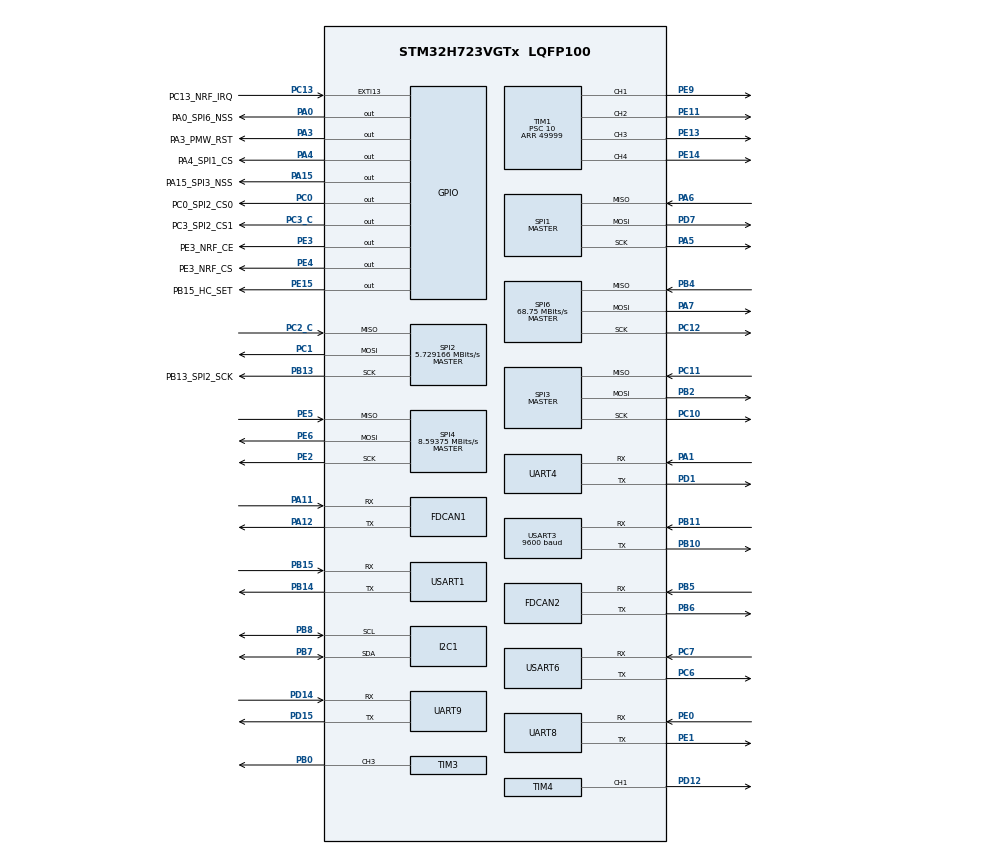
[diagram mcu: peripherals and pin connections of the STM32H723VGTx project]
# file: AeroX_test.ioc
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CORTEX_M7.default_mode_Activation=1
Dma.Request0=TIM4_CH1
Dma.Request1=UART4_RX
Dma.Request2=USART1_RX
Dma.TIM4_CH1.0.Direction=DMA_PERIPH_TO_MEMORY
Dma.TIM4_CH1.0.EventEnable=DISABLE
Dma.TIM4_CH1.0.FIFOMode=DMA_FIFOMODE_DISABLE
Dma.TIM4_CH1.0.Instance=DMA1_Stream0
Dma.TIM4_CH1.0.MemDataAlignment=DMA_MDATAALIGN_WORD
Dma.TIM4_CH1.0.MemInc=DMA_MINC_ENABLE
Dma.TIM4_CH1.0.Mode=DMA_CIRCULAR
Dma.TIM4_CH1.0.PeriphDataAlignment=DMA_PDATAALIGN_WORD
Dma.TIM4_CH1.0.PeriphInc=DMA_PINC_DISABLE
Dma.TIM4_CH1.0.Polarity=HAL_DMAMUX_REQ_GEN_RISING
Dma.TIM4_CH1.0.Priority=DMA_PRIORITY_LOW
Dma.TIM4_CH1.0.RequestNumber=1
Dma.TIM4_CH1.0.SignalID=NONE
Dma.TIM4_CH1.0.SyncEnable=DISABLE
Dma.TIM4_CH1.0.SyncPolarity=HAL_DMAMUX_SYNC_NO_EVENT
Dma.TIM4_CH1.0.SyncRequestNumber=1
Dma.TIM4_CH1.0.SyncSignalID=NONE
Dma.UART4_RX.1.Direction=DMA_PERIPH_TO_MEMORY
Dma.UART4_RX.1.EventEnable=DISABLE
Dma.UART4_RX.1.FIFOMode=DMA_FIFOMODE_DISABLE
Dma.UART4_RX.1.Instance=DMA1_Stream1
Dma.UART4_RX.1.MemDataAlignment=DMA_MDATAALIGN_BYTE
Dma.UART4_RX.1.MemInc=DMA_MINC_ENABLE
Dma.UART4_RX.1.Mode=DMA_CIRCULAR
Dma.UART4_RX.1.PeriphDataAlignment=DMA_PDATAALIGN_BYTE
Dma.UART4_RX.1.PeriphInc=DMA_PINC_DISABLE
Dma.UART4_RX.1.Polarity=HAL_DMAMUX_REQ_GEN_RISING
Dma.UART4_RX.1.Priority=DMA_PRIORITY_VERY_HIGH
Dma.UART4_RX.1.RequestNumber=1
Dma.UART4_RX.1.SignalID=NONE
Dma.UART4_RX.1.SyncEnable=DISABLE
Dma.UART4_RX.1.SyncPolarity=HAL_DMAMUX_SYNC_NO_EVENT
Dma.UART4_RX.1.SyncRequestNumber=1
Dma.UART4_RX.1.SyncSignalID=NONE
Dma.USART1_RX.2.Direction=DMA_PERIPH_TO_MEMORY
Dma.USART1_RX.2.EventEnable=DISABLE
Dma.USART1_RX.2.FIFOMode=DMA_FIFOMODE_DISABLE
Dma.USART1_RX.2.Instance=DMA1_Stream2
Dma.USART1_RX.2.MemDataAlignment=DMA_MDATAALIGN_BYTE
Dma.USART1_RX.2.MemInc=DMA_MINC_ENABLE
Dma.USART1_RX.2.Mode=DMA_NORMAL
Dma.USART1_RX.2.PeriphDataAlignment=DMA_PDATAALIGN_BYTE
Dma.USART1_RX.2.PeriphInc=DMA_PINC_DISABLE
Dma.USART1_RX.2.Polarity=HAL_DMAMUX_REQ_GEN_RISING
Dma.USART1_RX.2.Priority=DMA_PRIORITY_VERY_HIGH
Dma.USART1_RX.2.RequestNumber=1
Dma.USART1_RX.2.SignalID=NONE
Dma.USART1_RX.2.SyncEnable=DISABLE
Dma.USART1_RX.2.SyncPolarity=HAL_DMAMUX_SYNC_NO_EVENT
Dma.USART1_RX.2.SyncRequestNumber=1
Dma.USART1_RX.2.SyncSignalID=NONE
FDCAN1.CalculateBaudRateNominal=1612500
FDCAN1.CalculateTimeBitNominal=620
FDCAN1.CalculateTimeQuantumNominal=124.03100775193798
FDCAN2.CalculateBaudRateNominal=1612500
FDCAN2.CalculateTimeBitNominal=620
FDCAN2.CalculateTimeQuantumNominal=124.03100775193798
FREERTOS.Tasks01=defaultTask,24,512,StartDefaultTask,As weak,NULL,Dynamic,NULL,NULL;AttitudeIMUTask,32,512,StartAttitudeIMUTask,As weak,NULL,Dynamic,NULL,NULL;StabilizeTask,24,512,StartStabilizeTask,As weak,NULL,Dynamic,NULL,NULL;CommuCheckTask,8,256,StartCommuCheckTask,As weak,NULL,Dynamic,NULL,NULL;NrfResponseTask,8,256,StartNrfResponseTask,As weak,NULL,Dynamic,NULL,NULL;MoveTask,30,512,StartMoveTask,As weak,NULL,Dynamic,NULL,NULL
I2C1.Timing=0x60404E72
Mcu.Family=STM32H7
Mcu.Name=STM32H723VGTx
Mcu.Package=LQFP100
NVIC.DMA1_Stream0_IRQn=true\:5\:0\:false\:false\:true\:true\:false\:true\:true
NVIC.DMA1_Stream1_IRQn=true\:5\:0\:false\:false\:true\:true\:false\:true\:true
NVIC.DMA1_Stream2_IRQn=true\:5\:0\:false\:false\:true\:true\:false\:true\:true
NVIC.EXTI15_10_IRQn=true\:5\:0\:false\:false\:true\:true\:true\:true\:true
NVIC.PriorityGroup=NVIC_PRIORITYGROUP_4
NVIC.TIM6_DAC_IRQn=true\:5\:0\:false\:false\:true\:true\:true\:true\:true
NVIC.TIM7_IRQn=true\:15\:0\:false\:false\:true\:false\:false\:true\:true
NVIC.TimeBase=TIM7_IRQn
NVIC.TimeBaseIP=TIM7
NVIC.UART4_IRQn=true\:5\:0\:true\:false\:true\:true\:true\:true\:true
NVIC.UART8_IRQn=true\:5\:0\:false\:false\:true\:true\:true\:true\:true
NVIC.USART1_IRQn=true\:5\:0\:false\:false\:true\:true\:true\:true\:true
PA0.GPIO_Label=PA0_SPI6_NSS
PA0.Signal=GPIO_Output
PA1.Mode=Asynchronous
PA1.Signal=UART4_RX
PA11.Mode=FDCAN_Activate
PA11.Signal=FDCAN1_RX
PA12.Mode=FDCAN_Activate
PA12.Signal=FDCAN1_TX
PA13(JTMS/SWDIO).Mode=Serial_Wire
PA13(JTMS/SWDIO).Signal=DEBUG_JTMS-SWDIO
PA14(JTCK/SWCLK).Mode=Serial_Wire
PA14(JTCK/SWCLK).Signal=DEBUG_JTCK-SWCLK
PA15(JTDI).GPIO_Label=PA15_SPI3_NSS
PA15(JTDI).Signal=GPIO_Output
PA3.GPIO_Label=PA3_PMW_RST
PA3.Signal=GPIO_Output
PA4.GPIO_Label=PA4_SPI1_CS
PA4.Signal=GPIO_Output
PA5.Mode=Full_Duplex_Master
PA5.Signal=SPI1_SCK
PA6.Mode=Full_Duplex_Master
PA6.Signal=SPI1_MISO
PA7.Mode=Full_Duplex_Master
PA7.Signal=SPI6_MOSI
PB0.Signal=S_TIM3_CH3
PB10.Mode=Asynchronous
PB10.Signal=USART3_TX
PB11.Mode=Asynchronous
PB11.Signal=USART3_RX
PB13.GPIO_Label=PB13_SPI2_SCK
PB13.Mode=Full_Duplex_Master
PB13.Signal=SPI2_SCK
PB14.Mode=Asynchronous
PB14.Signal=USART1_TX
PB15.Mode=Asynchronous
PB15.Signal=USART1_RX
PB2.Mode=Full_Duplex_Master
PB2.Signal=SPI3_MOSI
PB4(NJTRST).Mode=Full_Duplex_Master
PB4(NJTRST).Signal=SPI6_MISO
PB5.Mode=FDCAN_Activate
PB5.Signal=FDCAN2_RX
PB6.Mode=FDCAN_Activate
PB6.Signal=FDCAN2_TX
PB7.Mode=I2C
PB7.Signal=I2C1_SDA
PB8.Mode=I2C
PB8.Signal=I2C1_SCL
PC0.GPIO_Label=PC0_SPI2_CS0
PC0.Signal=GPIO_Output
PC1.Mode=Full_Duplex_Master
PC1.Signal=SPI2_MOSI
PC10.Mode=Full_Duplex_Master
PC10.Signal=SPI3_SCK
PC11.Mode=Full_Duplex_Master
PC11.Signal=SPI3_MISO
PC12.Mode=Full_Duplex_Master
PC12.Signal=SPI6_SCK
PC13.GPIO_Label=PC13_NRF_IRQ
PC13.GPIO_ModeDefaultEXTI=GPIO_MODE_IT_FALLING
PC13.Signal=GPXTI13
PC2_C.Mode=Full_Duplex_Master
PC2_C.Signal=SPI2_MISO
PC3_C.GPIO_Label=PC3_SPI2_CS1
PC3_C.Signal=GPIO_Output
PC6.Mode=Asynchronous
PC6.Signal=USART6_TX
PC7.Mode=Asynchronous
PC7.Signal=USART6_RX
PD1.Mode=Asynchronous
PD1.Signal=UART4_TX
PD12.Signal=S_TIM4_CH1
PD14.Mode=Asynchronous
PD14.Signal=UART9_RX
PD15.Mode=Asynchronous
PD15.Signal=UART9_TX
PD7.Mode=Full_Duplex_Master
PD7.Signal=SPI1_MOSI
PE0.Mode=Asynchronous
PE0.Signal=UART8_RX
PE1.Mode=Asynchronous
PE1.Signal=UART8_TX
PE11.Signal=S_TIM1_CH2
PE13.Signal=S_TIM1_CH3
PE14.Signal=S_TIM1_CH4
PE15.GPIO_Label=PB15_HC_SET
PE15.PinState=GPIO_PIN_SET
PE15.Signal=GPIO_Output
PE2.Mode=Full_Duplex_Master
PE2.Signal=SPI4_SCK
PE3.GPIO_Label=PE3_NRF_CE
PE3.Signal=GPIO_Output
PE4.GPIO_Label=PE3_NRF_CS
PE4.Signal=GPIO_Output
PE5.Mode=Full_Duplex_Master
PE5.Signal=SPI4_MISO
PE6.Mode=Full_Duplex_Master
PE6.Signal=SPI4_MOSI
PE9.Signal=S_TIM1_CH1
ProjectManager.HeapSize=0x200
ProjectManager.StackSize=0x400
ProjectManager.TargetToolchain=MDK-ARM V5.32
RCC.ADCFreq_Value=129000000
RCC.APB1Freq_Value=137500000
RCC.APB2Freq_Value=137500000
RCC.APB3Freq_Value=137500000
RCC.APB4Freq_Value=137500000
RCC.CortexFreq_Value=550000000
RCC.D1PPRE=RCC_APB3_DIV2
RCC.D2PPRE1=RCC_APB1_DIV2
RCC.D2PPRE2=RCC_APB2_DIV2
RCC.D3PPRE=RCC_APB4_DIV2
RCC.DIVM1=4
RCC.DIVN1=34
RCC.DIVP1=1
RCC.DIVQ1=3
RCC.FDCANCLockSelection=RCC_FDCANCLKSOURCE_PLL2
RCC.HCLKFreq_Value=275000000
RCC.HPRE=RCC_HCLK_DIV2
RCC.HSE_VALUE=24000000
RCC.PLL2FRACN=0
RCC.PLL3FRACN=0
RCC.PLLFRACN=3072
RCC.SYSCLKFreq_VALUE=550000000
RCC.SYSCLKSource=RCC_SYSCLKSOURCE_PLLCLK
RCC.USBCLockSelection=RCC_USBCLKSOURCE_HSI48
RCC.USBFreq_Value=48000000
SH.S_TIM1_CH1.0=TIM1_CH1,PWM Generation1 CH1
SH.S_TIM1_CH2.0=TIM1_CH2,PWM Generation2 CH2
SH.S_TIM1_CH3.0=TIM1_CH3,PWM Generation3 CH3
SH.S_TIM1_CH4.0=TIM1_CH4,PWM Generation4 CH4
SH.S_TIM3_CH3.0=TIM3_CH3,PWM Generation3 CH3
SH.S_TIM4_CH1.0=TIM4_CH1,PWM Generation1 CH1
SPI1.CalculateBaudRate=91.666664 MBits/s
SPI1.Direction=SPI_DIRECTION_2LINES
SPI1.Mode=SPI_MODE_MASTER
SPI1.VirtualType=VM_MASTER
SPI2.BaudRatePrescaler=SPI_BAUDRATEPRESCALER_32
SPI2.CLKPhase=SPI_PHASE_2EDGE
SPI2.CLKPolarity=SPI_POLARITY_HIGH
SPI2.CalculateBaudRate=5.729166 MBits/s
SPI2.DataSize=SPI_DATASIZE_8BIT
SPI2.Direction=SPI_DIRECTION_2LINES
SPI2.Mode=SPI_MODE_MASTER
SPI2.VirtualType=VM_MASTER
SPI3.CalculateBaudRate=91.666664 MBits/s
SPI3.Direction=SPI_DIRECTION_2LINES
SPI3.Mode=SPI_MODE_MASTER
SPI3.VirtualType=VM_MASTER
SPI4.BaudRatePrescaler=SPI_BAUDRATEPRESCALER_16
SPI4.CalculateBaudRate=8.59375 MBits/s
SPI4.DataSize=SPI_DATASIZE_8BIT
SPI4.Direction=SPI_DIRECTION_2LINES
SPI4.Mode=SPI_MODE_MASTER
SPI4.VirtualType=VM_MASTER
SPI6.CalculateBaudRate=68.75 MBits/s
SPI6.Direction=SPI_DIRECTION_2LINES
SPI6.Mode=SPI_MODE_MASTER
SPI6.VirtualType=VM_MASTER
TIM1.Channel-PWM\ Generation1\ CH1=TIM_CHANNEL_1
TIM1.Channel-PWM\ Generation2\ CH2=TIM_CHANNEL_2
TIM1.Channel-PWM\ Generation3\ CH3=TIM_CHANNEL_3
TIM1.Channel-PWM\ Generation4\ CH4=TIM_CHANNEL_4
TIM1.Period=49999
TIM1.Prescaler=10
TIM3.Channel-PWM\ Generation3\ CH3=TIM_CHANNEL_3
TIM3.Period=343
TIM4.Channel-PWM\ Generation1\ CH1=TIM_CHANNEL_1
TIM4.Period=343
USART1.VirtualMode-Asynchronous=VM_ASYNC
USART3.BaudRate=9600
USART3.VirtualMode-Asynchronous=VM_ASYNC
USART6.VirtualMode=VM_ASYNC
VP_FREERTOS_VS_CMSIS_V2.Mode=CMSIS_V2
VP_MEMORYMAP_VS_MEMORYMAP.Mode=CurAppReg
VP_SYS_VS_tim7.Mode=TIM7
VP_TIM1_VS_ClockSourceINT.Mode=Internal
VP_TIM3_VS_ClockSourceINT.Mode=Internal
VP_TIM6_VS_ClockSourceINT.Mode=Enable_Timer
board=custom

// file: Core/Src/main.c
/* USER CODE BEGIN Header */
/**
  ******************************************************************************
  * @file           : main.c
  * @brief          : Main program body
  ******************************************************************************
  * @attention
  *
  * Copyright (c) 2025 STMicroelectronics.
  * All rights reserved.
  *
  * This software is licensed under terms that can be found in the LICENSE file
  * in the root directory of this software component.
  * If no LICENSE file comes with this software, it is provided AS-IS.
  *
  ******************************************************************************
  */
/* USER CODE END Header */
#include "main.h"
#include "cmsis_os.h"
#include "dma.h"
#include "fdcan.h"
#include "i2c.h"
#include "memorymap.h"
#include "spi.h"
#include "tim.h"
#include "usart.h"
#include "gpio.h"

/* USER CODE BEGIN Includes */
#include "test.h"
#include "appCallback.h"
/* USER CODE END Includes */

void SystemClock_Config(void);
void PeriphCommonClock_Config(void);
static void MPU_Config(void);
void MX_FREERTOS_Init(void);

int main(void)
{

  /* MPU Configuration--------------------------------------------------------*/
  MPU_Config();

  /* MCU Configuration--------------------------------------------------------*/

  /* Reset of all peripherals, Initializes the Flash interface and the Systick. */
  HAL_Init();

  /* Configure the system clock */
  SystemClock_Config();

  /* Configure the peripherals common clocks */
  PeriphCommonClock_Config();

  /* USER CODE BEGIN SysInit */
	if (__HAL_RCC_GET_FLAG(RCC_FLAG_BORRST) != RESET)
  {
	  __HAL_RCC_CLEAR_RESET_FLAGS();
	  HAL_Delay(200);
	  HAL_NVIC_SystemReset();
  }

  /* USER CODE END SysInit */

  /* Initialize all configured peripherals */
  MX_GPIO_Init();
  MX_DMA_Init();
  MX_SPI2_Init();
  MX_TIM1_Init();
  MX_TIM6_Init();
  MX_USART1_UART_Init();
  MX_USART3_UART_Init();
  MX_TIM3_Init();
  MX_SPI1_Init();
  MX_I2C1_Init();
  MX_SPI3_Init();
  MX_SPI4_Init();
  MX_SPI6_Init();
  MX_TIM4_Init();
  MX_UART4_Init();
  MX_UART8_Init();
  MX_UART9_Init();
  MX_USART6_UART_Init();
  MX_FDCAN1_Init();
  MX_FDCAN2_Init();

  /* Init scheduler */
  osKernelInitialize();

  /* Call init function for freertos objects (in cmsis_os2.c) */
  MX_FREERTOS_Init();

  /* Start scheduler */
  osKernelStart();

  /* We should never get here as control is now taken by the scheduler */

  /* Infinite loop */
  while (1)
  {

  }
}

void SystemClock_Config(void)
{
  RCC_OscInitTypeDef RCC_OscInitStruct = {0};
  RCC_ClkInitTypeDef RCC_ClkInitStruct = {0};

  /** Supply configuration update enable
  */
  HAL_PWREx_ConfigSupply(PWR_LDO_SUPPLY);

  /** Configure the main internal regulator output voltage
  */
  __HAL_PWR_VOLTAGESCALING_CONFIG(PWR_REGULATOR_VOLTAGE_SCALE0);

  while(!__HAL_PWR_GET_FLAG(PWR_FLAG_VOSRDY)) {}

  /** Initializes the RCC Oscillators according to the specified parameters
  * in the RCC_OscInitTypeDef structure.
  */
  RCC_OscInitStruct.OscillatorType = RCC_OSCILLATORTYPE_HSI;
  RCC_OscInitStruct.HSIState = RCC_HSI_DIV1;
  RCC_OscInitStruct.HSICalibrationValue = 64;
  RCC_OscInitStruct.PLL.PLLState = RCC_PLL_ON;
  RCC_OscInitStruct.PLL.PLLSource = RCC_PLLSOURCE_HSI;
  RCC_OscInitStruct.PLL.PLLM = 4;
  RCC_OscInitStruct.PLL.PLLN = 34;
  RCC_OscInitStruct.PLL.PLLP = 1;
  RCC_OscInitStruct.PLL.PLLQ = 3;
  RCC_OscInitStruct.PLL.PLLR = 2;
  RCC_OscInitStruct.PLL.PLLRGE = RCC_PLL1VCIRANGE_3;
  RCC_OscInitStruct.PLL.PLLVCOSEL = RCC_PLL1VCOWIDE;
  RCC_OscInitStruct.PLL.PLLFRACN = 3072;
  if (HAL_RCC_OscConfig(&RCC_OscInitStruct) != HAL_OK)
  {
    Error_Handler();
  }

  /** Initializes the CPU, AHB and APB buses clocks
  */
  RCC_ClkInitStruct.ClockType = RCC_CLOCKTYPE_HCLK|RCC_CLOCKTYPE_SYSCLK
                              |RCC_CLOCKTYPE_PCLK1|RCC_CLOCKTYPE_PCLK2
                              |RCC_CLOCKTYPE_D3PCLK1|RCC_CLOCKTYPE_D1PCLK1;
  RCC_ClkInitStruct.SYSCLKSource = RCC_SYSCLKSOURCE_PLLCLK;
  RCC_ClkInitStruct.SYSCLKDivider = RCC_SYSCLK_DIV1;
  RCC_ClkInitStruct.AHBCLKDivider = RCC_HCLK_DIV2;
  RCC_ClkInitStruct.APB3CLKDivider = RCC_APB3_DIV2;
  RCC_ClkInitStruct.APB1CLKDivider = RCC_APB1_DIV2;
  RCC_ClkInitStruct.APB2CLKDivider = RCC_APB2_DIV2;
  RCC_ClkInitStruct.APB4CLKDivider = RCC_APB4_DIV2;

  if (HAL_RCC_ClockConfig(&RCC_ClkInitStruct, FLASH_LATENCY_3) != HAL_OK)
  {
    Error_Handler();
  }
}

void PeriphCommonClock_Config(void)
{
  RCC_PeriphCLKInitTypeDef PeriphClkInitStruct = {0};

  /** Initializes the peripherals clock
  */
  PeriphClkInitStruct.PeriphClockSelection = RCC_PERIPHCLK_FDCAN;
  PeriphClkInitStruct.PLL2.PLL2M = 32;
  PeriphClkInitStruct.PLL2.PLL2N = 129;
  PeriphClkInitStruct.PLL2.PLL2P = 2;
  PeriphClkInitStruct.PLL2.PLL2Q = 2;
  PeriphClkInitStruct.PLL2.PLL2R = 2;
  PeriphClkInitStruct.PLL2.PLL2RGE = RCC_PLL2VCIRANGE_1;
  PeriphClkInitStruct.PLL2.PLL2VCOSEL = RCC_PLL2VCOWIDE;
  PeriphClkInitStruct.PLL2.PLL2FRACN = 0;
  PeriphClkInitStruct.FdcanClockSelection = RCC_FDCANCLKSOURCE_PLL2;
  if (HAL_RCCEx_PeriphCLKConfig(&PeriphClkInitStruct) != HAL_OK)
  {
    Error_Handler();
  }
}

/* USER CODE BEGIN 4 */

void HAL_GPIO_EXTI_Callback(uint16_t GPIO_Pin)
{
  APP_GPIO_EXTI_Callback(GPIO_Pin);
}

//串口空闲回调函数
void HAL_UART_RxCpltCallback(UART_HandleTypeDef *huart)
{
  APP_UART_RxCpltCallback(huart);
}

/* USER CODE END 4 */

 /* MPU Configuration */

void MPU_Config(void)
{
  MPU_Region_InitTypeDef MPU_InitStruct = {0};

  /* Disables the MPU */
  HAL_MPU_Disable();

  /** Initializes and configures the Region and the memory to be protected
  */
  MPU_InitStruct.Enable = MPU_REGION_ENABLE;
  MPU_InitStruct.Number = MPU_REGION_NUMBER0;
  MPU_InitStruct.BaseAddress = 0x0;
  MPU_InitStruct.Size = MPU_REGION_SIZE_4GB;
  MPU_InitStruct.SubRegionDisable = 0x87;
  MPU_InitStruct.TypeExtField = MPU_TEX_LEVEL0;
  MPU_InitStruct.AccessPermission = MPU_REGION_NO_ACCESS;
  MPU_InitStruct.DisableExec = MPU_INSTRUCTION_ACCESS_DISABLE;
  MPU_InitStruct.IsShareable = MPU_ACCESS_SHAREABLE;
  MPU_InitStruct.IsCacheable = MPU_ACCESS_NOT_CACHEABLE;
  MPU_InitStruct.IsBufferable = MPU_ACCESS_NOT_BUFFERABLE;

  HAL_MPU_ConfigRegion(&MPU_InitStruct);
  /* Enables the MPU */
  HAL_MPU_Enable(MPU_PRIVILEGED_DEFAULT);

}

void HAL_TIM_PeriodElapsedCallback(TIM_HandleTypeDef *htim)
{
  if (htim->Instance == TIM7) {
    HAL_IncTick();
  }
  /* USER CODE BEGIN Callback 1 */

  APP_TIM_PeriodElapsedCallback(htim);
  /* USER CODE END Callback 1 */
}

void Error_Handler(void)
{
  __disable_irq();
  while (1)
  {
  }
}

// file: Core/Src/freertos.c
/* USER CODE BEGIN Header */
/**
  ******************************************************************************
  * File Name          : freertos.c
  * Description        : Code for freertos applications
  ******************************************************************************
  * @attention
  *
  * Copyright (c) 2025 STMicroelectronics.
  * All rights reserved.
  *
  * This software is licensed under terms that can be found in the LICENSE file
  * in the root directory of this software component.
  * If no LICENSE file comes with this software, it is provided AS-IS.
  *
  ******************************************************************************
  */
/* USER CODE END Header */

#include "FreeRTOS.h"
#include "task.h"
#include "main.h"
#include "cmsis_os.h"

/* Definitions for defaultTask */
osThreadId_t defaultTaskHandle;
const osThreadAttr_t defaultTask_attributes = {
  .name = "defaultTask",
  .stack_size = 512 * 4,
  .priority = (osPriority_t) osPriorityNormal,
};
/* Definitions for AttitudeIMUTask */
osThreadId_t AttitudeIMUTaskHandle;
const osThreadAttr_t AttitudeIMUTask_attributes = {
  .name = "AttitudeIMUTask",
  .stack_size = 512 * 4,
  .priority = (osPriority_t) osPriorityAboveNormal,
};
/* Definitions for StabilizeTask */
osThreadId_t StabilizeTaskHandle;
const osThreadAttr_t StabilizeTask_attributes = {
  .name = "StabilizeTask",
  .stack_size = 512 * 4,
  .priority = (osPriority_t) osPriorityNormal,
};
/* Definitions for CommuCheckTask */
osThreadId_t CommuCheckTaskHandle;
const osThreadAttr_t CommuCheckTask_attributes = {
  .name = "CommuCheckTask",
  .stack_size = 256 * 4,
  .priority = (osPriority_t) osPriorityLow,
};
/* Definitions for NrfResponseTask */
osThreadId_t NrfResponseTaskHandle;
const osThreadAttr_t NrfResponseTask_attributes = {
  .name = "NrfResponseTask",
  .stack_size = 256 * 4,
  .priority = (osPriority_t) osPriorityLow,
};
/* Definitions for MoveTask */
osThreadId_t MoveTaskHandle;
const osThreadAttr_t MoveTask_attributes = {
  .name = "MoveTask",
  .stack_size = 512 * 4,
  .priority = (osPriority_t) osPriorityNormal6,
};

void StartDefaultTask(void *argument);
void StartAttitudeIMUTask(void *argument);
void StartStabilizeTask(void *argument);
void StartCommuCheckTask(void *argument);
void StartNrfResponseTask(void *argument);
void StartMoveTask(void *argument);

void MX_FREERTOS_Init(void); /* (MISRA C 2004 rule 8.1) */

void MX_FREERTOS_Init(void) {

  /* Create the thread(s) */
  /* creation of defaultTask */
  defaultTaskHandle = osThreadNew(StartDefaultTask, NULL, &defaultTask_attributes);

  /* creation of AttitudeIMUTask */
  AttitudeIMUTaskHandle = osThreadNew(StartAttitudeIMUTask, NULL, &AttitudeIMUTask_attributes);

  /* creation of StabilizeTask */
  StabilizeTaskHandle = osThreadNew(StartStabilizeTask, NULL, &StabilizeTask_attributes);

  /* creation of CommuCheckTask */
  CommuCheckTaskHandle = osThreadNew(StartCommuCheckTask, NULL, &CommuCheckTask_attributes);

  /* creation of NrfResponseTask */
  NrfResponseTaskHandle = osThreadNew(StartNrfResponseTask, NULL, &NrfResponseTask_attributes);

  /* creation of MoveTask */
  MoveTaskHandle = osThreadNew(StartMoveTask, NULL, &MoveTask_attributes);

}

__weak void StartDefaultTask(void *argument)
{
  for(;;)
  {
    osDelay(1);
  }
}

__weak void StartAttitudeIMUTask(void *argument)
{
  for(;;)
  {
    osDelay(1);
  }
}

__weak void StartStabilizeTask(void *argument)
{
  for(;;)
  {
    osDelay(1);
  }
}

__weak void StartCommuCheckTask(void *argument)
{
  for(;;)
  {
    osDelay(1);
  }
}

__weak void StartNrfResponseTask(void *argument)
{
  for(;;)
  {
    osDelay(1);
  }
}

__weak void StartMoveTask(void *argument)
{
  for(;;)
  {
    osDelay(1);
  }
}
